# APM32F00x register map
File version: 1.0
CPU: CM0+ r0p1, little endian, no MPU, no FPU, 4 interrupt priority bits
Registers are 32-bit, read-write, reset 0x0 unless marked. A register's access mark holds for its fields unless they carry their own. Offsets are from the block's base; [hi:lo] are bit positions; {n}, {i} and the like mark numbered series.

## TMR1 — 16-bit timer with complementary PWM outputs
Base 0x40003800
Same registers: TMR1A 0x40001000
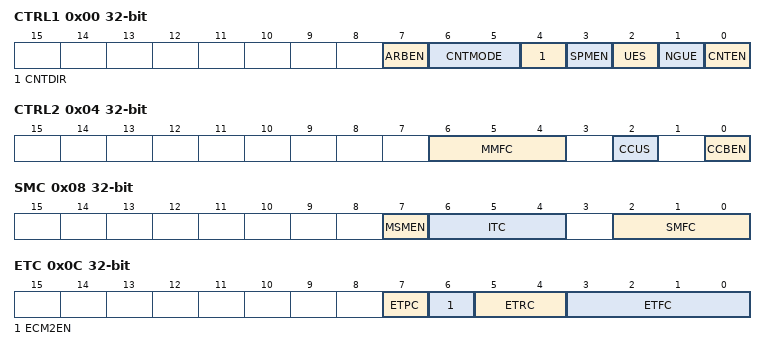
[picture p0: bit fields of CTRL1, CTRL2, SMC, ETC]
0x00 CTRL1 — control register 1
  [7] ARBEN — Auto-Reload Preload Enable
  [6:5] CNTMODE — Center-aligned Mode Selection
  [4] CNTDIR — Counter Direction
  [3] SPMEN — Single Pulse Mode Enable
  [2] UES — Update Event Source
  [1] NGUE — No Generated Update Event
  [0] CNTEN — Counter Enable
0x04 CTRL2 — control register 2
  [6:4] MMFC — Master Mode Function Configure
  [2] CCUS — Capture/Compare Control Update Selection
  [0] CCBEN — Capture/Compare Preloaded Enable
0x08 SMC — Synchro mode control register
  [7] MSMEN — Master/slave Mode Enable
  [6:4] ITC — Input Trigger Configure
  [2:0] SMFC — Slave Mode Function Configure
0x0C ETC — external trigger register
  [7] ETPC — External Trigger Polarity mask.
  [6] ECM2EN — External Clock mask.
  [5:4] ETRC — External Trigger Prescaler mask.
  [3:0] ETFC — External Trigger Filter mask.
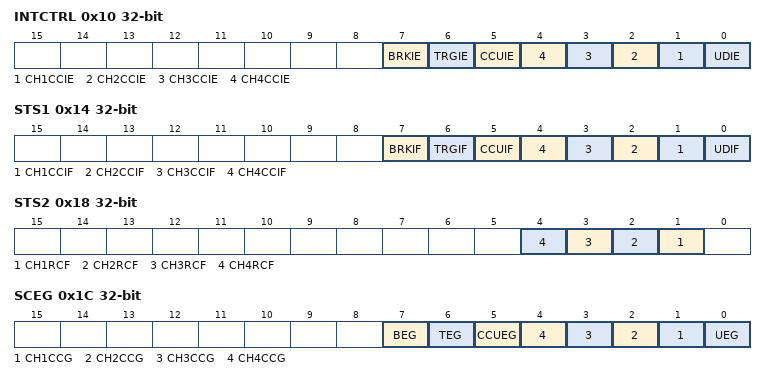
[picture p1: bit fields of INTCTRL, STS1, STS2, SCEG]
0x10 INTCTRL — interrupt enable register
  [7] BRKIE — Break Interrupt Enable mask.
  [6] TRGIE — Trigger Interrupt Enable mask.
  [5] CCUIE — Commutation Interrupt Enable mask.
  [n] CH{n}CCIE (n=1..4) — Capture/Compare {n} Interrupt Enable mask.
  [0] UDIE — Update Interrupt Enable mask.
0x14 STS1 — status register 1
  [7] BRKIF — Break Interrupt Flag mask.
  [6] TRGIF — Trigger Interrupt Flag mask.
  [5] CCUIF — Commutation Interrupt Flag mask.
  [n] CH{n}CCIF (n=1..4) — Capture/Compare {n} Interrupt Flag mask.
  [0] UDIF — Update Interrupt Flag mask.
0x18 STS2 — status register 2
  [n] CH{n}RCF (n=1..4) — Capture/Compare {n} Overcapture Flag mask.
0x1C SCEG — event generation register
  [7] BEG — Break Generation mask.
  [6] TEG — Trigger Generation mask.
  [5] CCUEG — Capture/Compare Control Update Generation mask.
  [n] CH{n}CCG (n=1..4) — Capture/Compare {n} Generation mask.
  [0] UEG — Update Generation mask.
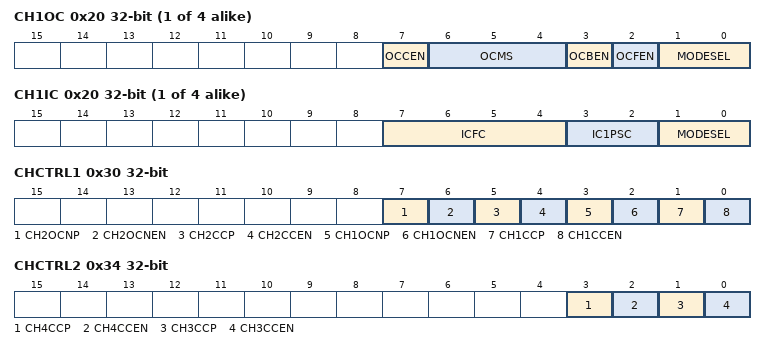
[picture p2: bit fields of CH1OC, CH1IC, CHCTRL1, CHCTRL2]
{0x1C+4i} CH{i}OC (i=1..4) — CC mode register {i}
  [7] OCCEN — Input Capture {i} Filter mask.
  [6:4] OCMS — Output Compare {i} Mode mask.
  [3] OCBEN — Output Compare {i} Preload Enable mask.
  [2] OCFEN — Output Compare {i} Fast Enable mask.
  [1:0] MODESEL — Capture/Compare {i} Selection mask.
{0x1C+4i} CH{i}IC (alternate view of CH{i}OC) (i=1..4) — IC mode register {i}
  [7:4] ICFC — Input Capture Channel{i} Filter Configure
  [3:2] IC{i}PSC — Input Capture Channel{i} Perscaler Configure
  [1:0] MODESEL — Capture/Compare 1 Selection mask.
0x30 CHCTRL1 — CC enable register 1
  [7] CH2OCNP — Capture/Compare 2 Complementary output Polarity mask.
  [6] CH2OCNEN — Capture/Compare 2 Complementary output enable mask.
  [5] CH2CCP — Capture/Compare 2 output Polarity mask.
  [4] CH2CCEN — Capture/Compare 2 output enable mask.
  [3] CH1OCNP — Capture/Compare 1 Complementary output Polarity mask.
  [2] CH1OCNEN — Capture/Compare 1 Complementary output enable mask.
  [1] CH1CCP — Capture/Compare 1 output Polarity mask.
  [0] CH1CCEN — Capture/Compare 1 output enable mask.
0x34 CHCTRL2 — CC enable register 2
  [3] CH4CCP — Capture/Compare 3 Complementary output Polarity mask.
  [2] CH4CCEN — Capture/Compare 3 Complementary output enable mask.
  [1] CH3CCP — Capture/Compare 3 output Polarity mask.
  [0] CH3CCEN — Capture/Compare 3 output enable mask.
0x38 CNT1 — counter high
  [7:0] CNT[15_8] — Counter Value (MSB) mask.
0x3C CNT0 — counter low
  [7:0] CNT[7_0] — Counter Value (LSB) mask.
0x40 PSC1 — prescaler high
  [7:0] PSC[15_8] — Prescaler Value (MSB) mask.
0x44 PSC0 — prescaler low
  [7:0] PSC[7_0] — Prescaler Value (LSB) mask.
0x48 AUTORLD1 — auto-reload register high
  [7:0] AUTORLD[15_8] — Autoreload Value (MSB) mask.
0x4C AUTORLD0 — auto-reload register low
  [7:0] AUTORLD[7_0] — Autoreload Value (LSB) mask.
0x50 REPCNT reset 0xFF — Repetition Counter register
  [7:0] REPCNT — Repetition Counter Value mask.
{0x4C+8i} CH{i}CC1 (i=1..4) — capture/compare register {i} high
  [7:0] CC — Capture/Compare {i} Value (MSB) mask.
{0x50+8i} CH{i}CC0 (i=1..3) — capture/compare register {i} low
  [7:0] CC — Capture/Compare {i} Value (LSB) mask.
0x70 CH4CC0 reset 0xFFF — capture/compare register 4 low
  [7:0] CC — Capture/Compare 4 Value (LSB) mask.
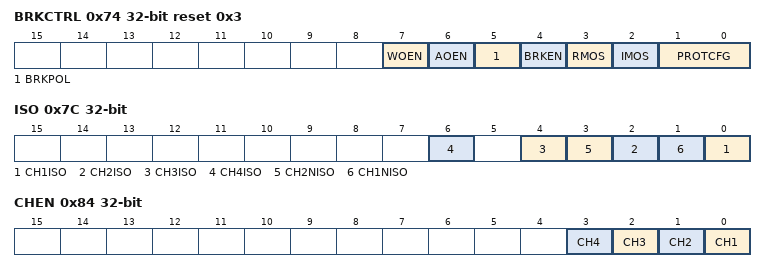
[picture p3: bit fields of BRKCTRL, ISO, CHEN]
0x74 BRKCTRL reset 0x3 — Break Register
  [7] WOEN — Main Output Enable mask.
  [6] AOEN — Automatic Output Enable mask.
  [5] BRKPOL — Break Polarity mask.
  [4] BRKEN — Break Enable mask.
  [3] RMOS — Off-State Selection for Run mode mask.
  [2] IMOS — Off-State Selection for Idle mode mask.
  [1:0] PROTCFG — Lock Configuration mask.
0x78 DTS — dead-time register
  [7:0] DTS — Dead-Time Generator set-up mask.
0x7C ISO — Output idle register
  [2n-2] CH{n}ISO (n=1..4) — Output Idle state {n} (OC{n} output) mask.
  [3] CH2NISO — Output Idle state 2 (OC2N output) mask.
  [1] CH1NISO — Output Idle state 1 (OC1N output) mask.
0x84 CHEN — Timer1A Channel enable register
  [n-1] CH{n} (n=1..4)
